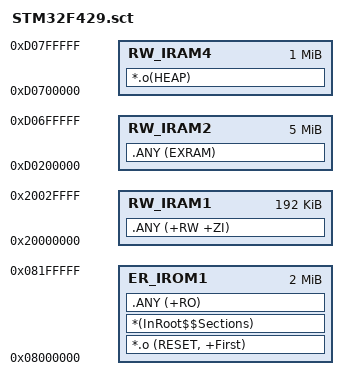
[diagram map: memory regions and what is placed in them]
LR_IROM1 0x08000000 0x00200000  {    ; load region size_region
  ER_IROM1 0x08000000 0x00200000  {  ; load address = execution address
   *.o (RESET, +First)
   *(InRoot$$Sections)
   .ANY (+RO)
  }
  RW_IRAM1 0x20000000 0x00030000  {  ; RW data
   .ANY (+RW +ZI)
  }
  RW_IRAM2 0xD0200000 0x00500000  {  ; RW data
   .ANY (EXRAM);extern ram
  }
  RW_IRAM4 0xD0700000 0x00100000  {  ; RW data
   *.o(HEAP)
  }
}
